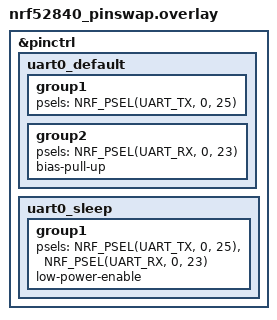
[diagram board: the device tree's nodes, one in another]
/*
 * MTIB REV 1.1 UART pin swap compensation — nRF52840 (Alpha B0).
 *
 * REV 1.1 carrier board has UART TX/RX traces physically swapped.
 * This overlay swaps the nRF52840 UART0 pin assignments to compensate.
 * Not needed on REV 1.2 (fixed in hardware).
 *
 * Base DTS: TX=P0.23, RX=P0.25
 * This overlay: TX=P0.25, RX=P0.23 (swapped)
 *
 * Apply via: -DDTC_OVERLAY_FILE="...;overlays/nrf52840_pinswap.overlay"
 */

&pinctrl {
    uart0_default: uart0_default {
        group1 {
            psels = <NRF_PSEL(UART_TX, 0, 25)>;
        };
        group2 {
            psels = <NRF_PSEL(UART_RX, 0, 23)>;
            bias-pull-up;
        };
    };

    uart0_sleep: uart0_sleep {
        group1 {
            psels = <NRF_PSEL(UART_TX, 0, 25)>,
                    <NRF_PSEL(UART_RX, 0, 23)>;
            low-power-enable;
        };
    };
};
